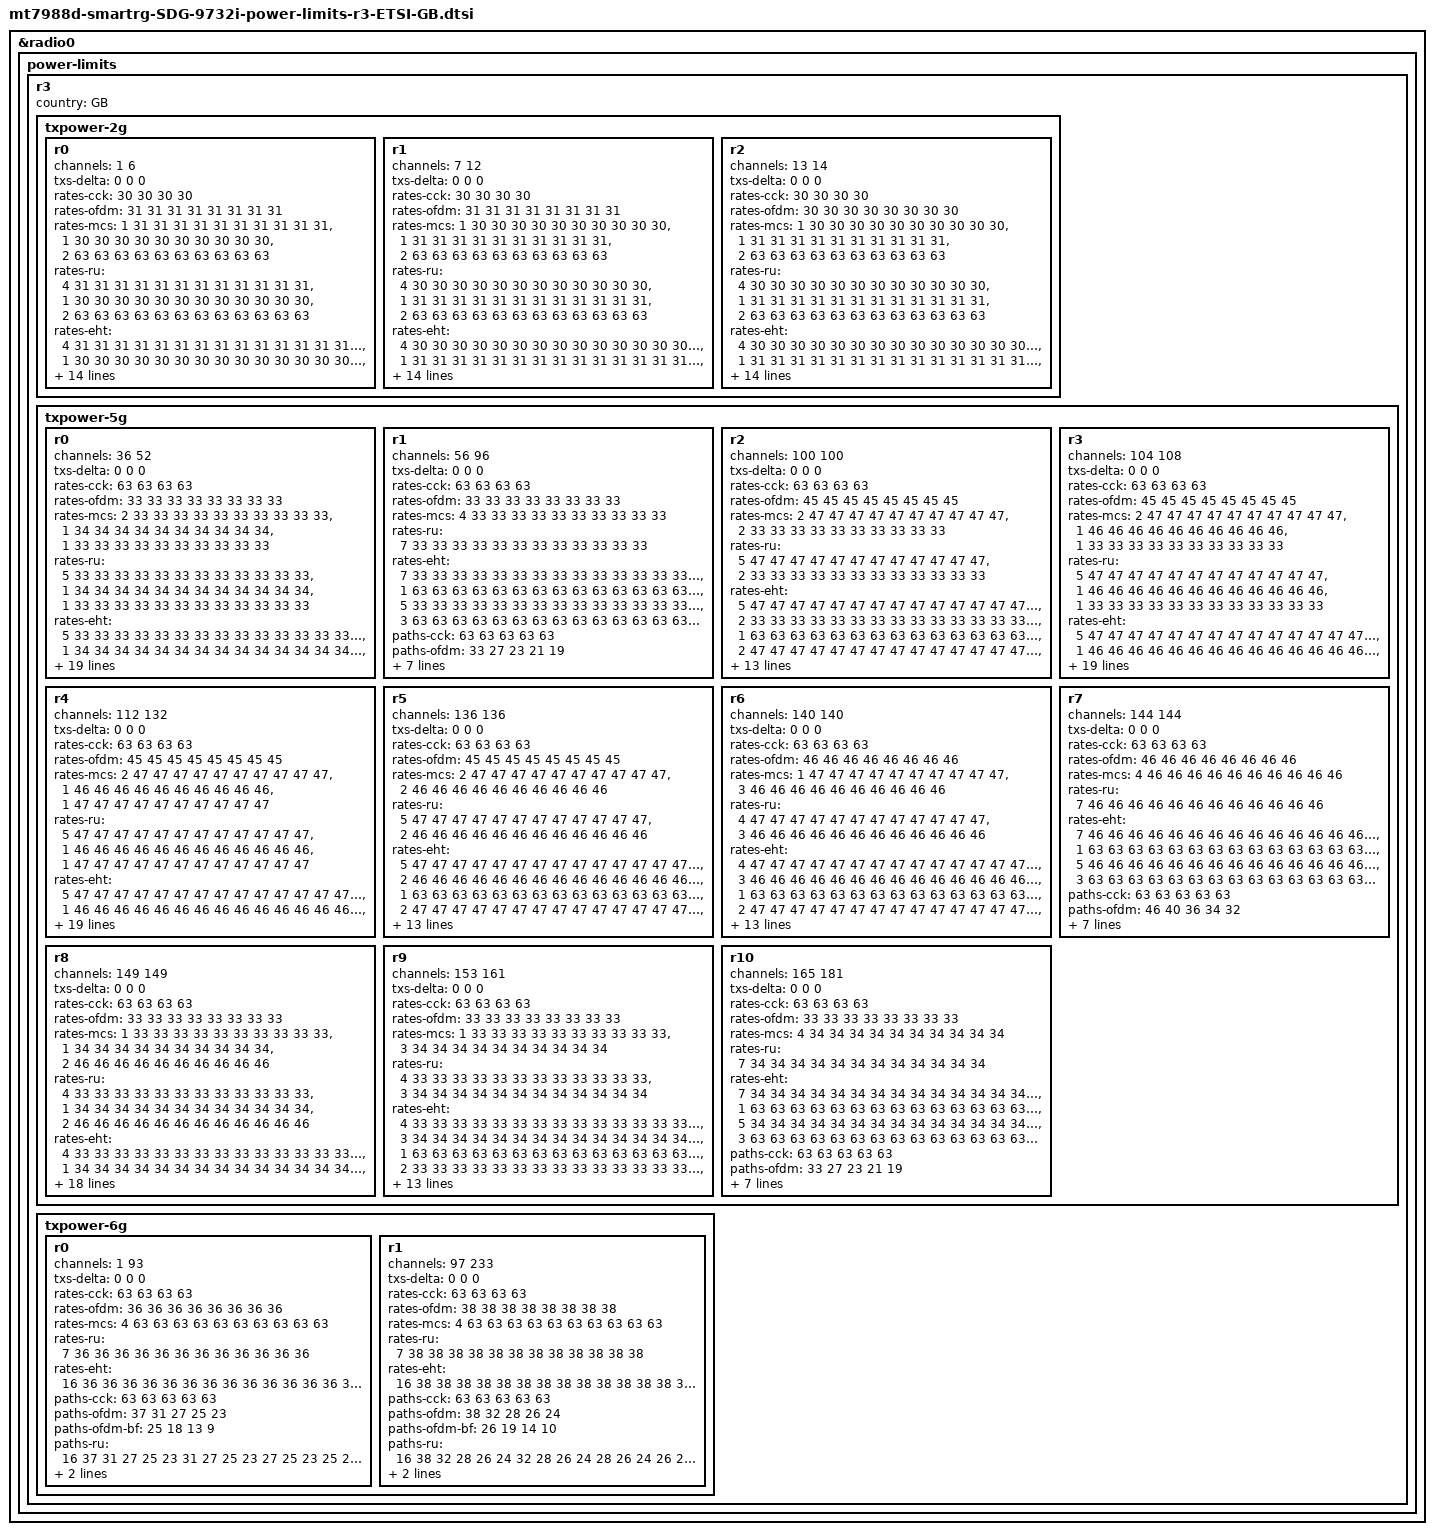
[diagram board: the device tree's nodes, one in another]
// SPDX-License-Identifier: (GPL-2.0 OR MIT)
/*
 * Copyright (C) 2024 SmartRG Inc.
 * Author: Chad Monroe <chad.monroe@smartrg.com>
 */

&radio0 {
	power-limits {
		r3 {
			country = "GB";

			txpower-2g {
				r0 {
					channels = <1 6>;
					txs-delta = <0 0 0>;
					rates-cck = /bits/ 8 <30 30 30 30>;
					rates-ofdm = /bits/ 8 <31 31 31 31 31 31 31 31>;
					rates-mcs =
					/bits/ 8 <1 31 31 31 31 31 31 31 31 31 31>,
					/bits/ 8 <1 30 30 30 30 30 30 30 30 30 30>,
					/bits/ 8 <2 63 63 63 63 63 63 63 63 63 63>;
					rates-ru =
					/bits/ 8 <4 31 31 31 31 31 31 31 31 31 31 31 31>,
					/bits/ 8 <1 30 30 30 30 30 30 30 30 30 30 30 30>,
					/bits/ 8 <2 63 63 63 63 63 63 63 63 63 63 63 63>;
					rates-eht =
					/bits/ 8 <4 31 31 31 31 31 31 31 31 31 31 31 31 31 31 31 31>,
					/bits/ 8 <1 30 30 30 30 30 30 30 30 30 30 30 30 30 30 30 30>,
					/bits/ 8 <3 63 63 63 63 63 63 63 63 63 63 63 63 63 63 63 63>,
					/bits/ 8 <2 31 31 31 31 31 31 31 31 31 31 31 31 31 31 31 31>,
					/bits/ 8 <6 63 63 63 63 63 63 63 63 63 63 63 63 63 63 63 63>;
					paths-cck = /bits/ 8 <30 24 20 18 16>;
					paths-ofdm = /bits/ 8 <31 25 21 19 17>;
					paths-ofdm-bf = /bits/ 8 <19 12 7 3>;
					paths-ru =
					/bits/ 8 <6 31 25 21 19 17 25 21 19 17 21 19 17 19 17 17>,
					/bits/ 8 <1 30 24 20 18 16 24 20 18 16 20 18 16 18 16 16>,
					/bits/ 8 <9 63 63 63 63 63 63 63 63 63 63 63 63 63 63 63>;
					paths-ru-bf =
					/bits/ 8 <6 31 19 12 7 3 25 18 13 9 21 16 13 19 15 17>,
					/bits/ 8 <1 30 18 11 6 2 24 17 12 8 20 15 12 18 14 16>,
					/bits/ 8 <9 63 63 63 63 63 63 63 63 63 63 63 63 63 63 63>;
				};
				r1 {
					channels = <7 12>;
					txs-delta = <0 0 0>;
					rates-cck = /bits/ 8 <30 30 30 30>;
					rates-ofdm = /bits/ 8 <31 31 31 31 31 31 31 31>;
					rates-mcs =
					/bits/ 8 <1 30 30 30 30 30 30 30 30 30 30>,
					/bits/ 8 <1 31 31 31 31 31 31 31 31 31 31>,
					/bits/ 8 <2 63 63 63 63 63 63 63 63 63 63>;
					rates-ru =
					/bits/ 8 <4 30 30 30 30 30 30 30 30 30 30 30 30>,
					/bits/ 8 <1 31 31 31 31 31 31 31 31 31 31 31 31>,
					/bits/ 8 <2 63 63 63 63 63 63 63 63 63 63 63 63>;
					rates-eht =
					/bits/ 8 <4 30 30 30 30 30 30 30 30 30 30 30 30 30 30 30 30>,
					/bits/ 8 <1 31 31 31 31 31 31 31 31 31 31 31 31 31 31 31 31>,
					/bits/ 8 <3 63 63 63 63 63 63 63 63 63 63 63 63 63 63 63 63>,
					/bits/ 8 <2 30 30 30 30 30 30 30 30 30 30 30 30 30 30 30 30>,
					/bits/ 8 <6 63 63 63 63 63 63 63 63 63 63 63 63 63 63 63 63>;
					paths-cck = /bits/ 8 <30 24 20 18 16>;
					paths-ofdm = /bits/ 8 <31 25 21 19 17>;
					paths-ofdm-bf = /bits/ 8 <19 12 7 3>;
					paths-ru =
					/bits/ 8 <6 30 24 20 18 16 24 20 18 16 20 18 16 18 16 16>,
					/bits/ 8 <1 31 25 21 19 17 25 21 19 17 21 19 17 19 17 17>,
					/bits/ 8 <9 63 63 63 63 63 63 63 63 63 63 63 63 63 63 63>;
					paths-ru-bf =
					/bits/ 8 <6 30 18 11 6 2 24 17 12 8 20 15 12 18 14 16>,
					/bits/ 8 <1 31 19 12 7 3 25 18 13 9 21 16 13 19 15 17>,
					/bits/ 8 <9 63 63 63 63 63 63 63 63 63 63 63 63 63 63 63>;
				};
				r2 {
					channels = <13 14>;
					txs-delta = <0 0 0>;
					rates-cck = /bits/ 8 <30 30 30 30>;
					rates-ofdm = /bits/ 8 <30 30 30 30 30 30 30 30>;
					rates-mcs =
					/bits/ 8 <1 30 30 30 30 30 30 30 30 30 30>,
					/bits/ 8 <1 31 31 31 31 31 31 31 31 31 31>,
					/bits/ 8 <2 63 63 63 63 63 63 63 63 63 63>;
					rates-ru =
					/bits/ 8 <4 30 30 30 30 30 30 30 30 30 30 30 30>,
					/bits/ 8 <1 31 31 31 31 31 31 31 31 31 31 31 31>,
					/bits/ 8 <2 63 63 63 63 63 63 63 63 63 63 63 63>;
					rates-eht =
					/bits/ 8 <4 30 30 30 30 30 30 30 30 30 30 30 30 30 30 30 30>,
					/bits/ 8 <1 31 31 31 31 31 31 31 31 31 31 31 31 31 31 31 31>,
					/bits/ 8 <3 63 63 63 63 63 63 63 63 63 63 63 63 63 63 63 63>,
					/bits/ 8 <2 30 30 30 30 30 30 30 30 30 30 30 30 30 30 30 30>,
					/bits/ 8 <6 63 63 63 63 63 63 63 63 63 63 63 63 63 63 63 63>;
					paths-cck = /bits/ 8 <30 24 20 18 16>;
					paths-ofdm = /bits/ 8 <30 24 20 18 16>;
					paths-ofdm-bf = /bits/ 8 <18 11 6 2>;
					paths-ru =
					/bits/ 8 <6 30 24 20 18 16 24 20 18 16 20 18 16 18 16 16>,
					/bits/ 8 <1 31 25 21 19 17 25 21 19 17 21 19 17 19 17 17>,
					/bits/ 8 <9 63 63 63 63 63 63 63 63 63 63 63 63 63 63 63>;
					paths-ru-bf =
					/bits/ 8 <6 30 18 11 6 2 24 17 12 8 20 15 12 18 14 16>,
					/bits/ 8 <1 31 19 12 7 3 25 18 13 9 21 16 13 19 15 17>,
					/bits/ 8 <9 63 63 63 63 63 63 63 63 63 63 63 63 63 63 63>;
				};
			};
			txpower-5g {
				r0 {
					channels = <36 52>;
					txs-delta = <0 0 0>;
					rates-cck = /bits/ 8 <63 63 63 63>;
					rates-ofdm = /bits/ 8 <33 33 33 33 33 33 33 33>;
					rates-mcs =
					/bits/ 8 <2 33 33 33 33 33 33 33 33 33 33>,
					/bits/ 8 <1 34 34 34 34 34 34 34 34 34 34>,
					/bits/ 8 <1 33 33 33 33 33 33 33 33 33 33>;
					rates-ru =
					/bits/ 8 <5 33 33 33 33 33 33 33 33 33 33 33 33>,
					/bits/ 8 <1 34 34 34 34 34 34 34 34 34 34 34 34>,
					/bits/ 8 <1 33 33 33 33 33 33 33 33 33 33 33 33>;
					rates-eht =
					/bits/ 8 <5 33 33 33 33 33 33 33 33 33 33 33 33 33 33 33 33>,
					/bits/ 8 <1 34 34 34 34 34 34 34 34 34 34 34 34 34 34 34 34>,
					/bits/ 8 <1 33 33 33 33 33 33 33 33 33 33 33 33 33 33 33 33>,
					/bits/ 8 <1 63 63 63 63 63 63 63 63 63 63 63 63 63 63 63 63>,
					/bits/ 8 <2 33 33 33 33 33 33 33 33 33 33 33 33 33 33 33 33>,
					/bits/ 8 <1 34 34 34 34 34 34 34 34 34 34 34 34 34 34 34 34>,
					/bits/ 8 <2 33 33 33 33 33 33 33 33 33 33 33 33 33 33 33 33>,
					/bits/ 8 <3 63 63 63 63 63 63 63 63 63 63 63 63 63 63 63 63>;
					paths-cck = /bits/ 8 <63 63 63 63 63>;
					paths-ofdm = /bits/ 8 <33 27 23 21 19>;
					paths-ofdm-bf = /bits/ 8 <21 14 9 5>;
					paths-ru =
					/bits/ 8 <7 33 27 23 21 19 27 23 21 19 23 21 19 21 19 19>,
					/bits/ 8 <2 34 28 24 22 20 28 24 22 20 24 22 20 22 20 20>,
					/bits/ 8 <3 33 27 23 21 19 27 23 21 19 23 21 19 21 19 19>,
					/bits/ 8 <4 63 63 63 63 63 63 63 63 63 63 63 63 63 63 63>;
					paths-ru-bf =
					/bits/ 8 <7 33 21 14 9 5 27 20 15 11 23 18 15 21 17 19>,
					/bits/ 8 <2 34 22 15 10 6 28 21 16 12 24 19 16 22 18 20>,
					/bits/ 8 <3 33 21 14 9 5 27 20 15 11 23 18 15 21 17 19>,
					/bits/ 8 <4 63 63 63 63 63 63 63 63 63 63 63 63 63 63 63>;
				};
				r1 {
					channels = <56 96>;
					txs-delta = <0 0 0>;
					rates-cck = /bits/ 8 <63 63 63 63>;
					rates-ofdm = /bits/ 8 <33 33 33 33 33 33 33 33>;
					rates-mcs =
					/bits/ 8 <4 33 33 33 33 33 33 33 33 33 33>;
					rates-ru =
					/bits/ 8 <7 33 33 33 33 33 33 33 33 33 33 33 33>;
					rates-eht =
					/bits/ 8 <7 33 33 33 33 33 33 33 33 33 33 33 33 33 33 33 33>,
					/bits/ 8 <1 63 63 63 63 63 63 63 63 63 63 63 63 63 63 63 63>,
					/bits/ 8 <5 33 33 33 33 33 33 33 33 33 33 33 33 33 33 33 33>,
					/bits/ 8 <3 63 63 63 63 63 63 63 63 63 63 63 63 63 63 63 63>;
					paths-cck = /bits/ 8 <63 63 63 63 63>;
					paths-ofdm = /bits/ 8 <33 27 23 21 19>;
					paths-ofdm-bf = /bits/ 8 <21 14 9 5>;
					paths-ru =
					/bits/ 8 <12 33 27 23 21 19 27 23 21 19 23 21 19 21 19 19>,
					/bits/ 8 <4 63 63 63 63 63 63 63 63 63 63 63 63 63 63 63>;
					paths-ru-bf =
					/bits/ 8 <12 33 21 14 9 5 27 20 15 11 23 18 15 21 17 19>,
					/bits/ 8 <4 63 63 63 63 63 63 63 63 63 63 63 63 63 63 63>;
				};
				r2 {
					channels = <100 100>;
					txs-delta = <0 0 0>;
					rates-cck = /bits/ 8 <63 63 63 63>;
					rates-ofdm = /bits/ 8 <45 45 45 45 45 45 45 45>;
					rates-mcs =
					/bits/ 8 <2 47 47 47 47 47 47 47 47 47 47>,
					/bits/ 8 <2 33 33 33 33 33 33 33 33 33 33>;
					rates-ru =
					/bits/ 8 <5 47 47 47 47 47 47 47 47 47 47 47 47>,
					/bits/ 8 <2 33 33 33 33 33 33 33 33 33 33 33 33>;
					rates-eht =
					/bits/ 8 <5 47 47 47 47 47 47 47 47 47 47 47 47 47 47 47 47>,
					/bits/ 8 <2 33 33 33 33 33 33 33 33 33 33 33 33 33 33 33 33>,
					/bits/ 8 <1 63 63 63 63 63 63 63 63 63 63 63 63 63 63 63 63>,
					/bits/ 8 <2 47 47 47 47 47 47 47 47 47 47 47 47 47 47 47 47>,
					/bits/ 8 <3 33 33 33 33 33 33 33 33 33 33 33 33 33 33 33 33>,
					/bits/ 8 <3 63 63 63 63 63 63 63 63 63 63 63 63 63 63 63 63>;
					paths-cck = /bits/ 8 <63 63 63 63 63>;
					paths-ofdm = /bits/ 8 <45 39 35 33 31>;
					paths-ofdm-bf = /bits/ 8 <33 26 21 17>;
					paths-ru =
					/bits/ 8 <7 47 41 37 35 33 41 37 35 33 37 35 33 35 33 33>,
					/bits/ 8 <5 33 27 23 21 19 27 23 21 19 23 21 19 21 19 19>,
					/bits/ 8 <4 63 63 63 63 63 63 63 63 63 63 63 63 63 63 63>;
					paths-ru-bf =
					/bits/ 8 <7 47 35 28 23 19 41 34 29 25 37 32 29 35 31 33>,
					/bits/ 8 <5 33 21 14 9 5 27 20 15 11 23 18 15 21 17 19>,
					/bits/ 8 <4 63 63 63 63 63 63 63 63 63 63 63 63 63 63 63>;
				};
				r3 {
					channels = <104 108>;
					txs-delta = <0 0 0>;
					rates-cck = /bits/ 8 <63 63 63 63>;
					rates-ofdm = /bits/ 8 <45 45 45 45 45 45 45 45>;
					rates-mcs =
					/bits/ 8 <2 47 47 47 47 47 47 47 47 47 47>,
					/bits/ 8 <1 46 46 46 46 46 46 46 46 46 46>,
					/bits/ 8 <1 33 33 33 33 33 33 33 33 33 33>;
					rates-ru =
					/bits/ 8 <5 47 47 47 47 47 47 47 47 47 47 47 47>,
					/bits/ 8 <1 46 46 46 46 46 46 46 46 46 46 46 46>,
					/bits/ 8 <1 33 33 33 33 33 33 33 33 33 33 33 33>;
					rates-eht =
					/bits/ 8 <5 47 47 47 47 47 47 47 47 47 47 47 47 47 47 47 47>,
					/bits/ 8 <1 46 46 46 46 46 46 46 46 46 46 46 46 46 46 46 46>,
					/bits/ 8 <1 33 33 33 33 33 33 33 33 33 33 33 33 33 33 33 33>,
					/bits/ 8 <1 63 63 63 63 63 63 63 63 63 63 63 63 63 63 63 63>,
					/bits/ 8 <2 47 47 47 47 47 47 47 47 47 47 47 47 47 47 47 47>,
					/bits/ 8 <1 46 46 46 46 46 46 46 46 46 46 46 46 46 46 46 46>,
					/bits/ 8 <2 33 33 33 33 33 33 33 33 33 33 33 33 33 33 33 33>,
					/bits/ 8 <3 63 63 63 63 63 63 63 63 63 63 63 63 63 63 63 63>;
					paths-cck = /bits/ 8 <63 63 63 63 63>;
					paths-ofdm = /bits/ 8 <45 39 35 33 31>;
					paths-ofdm-bf = /bits/ 8 <33 26 21 17>;
					paths-ru =
					/bits/ 8 <7 47 41 37 35 33 41 37 35 33 37 35 33 35 33 33>,
					/bits/ 8 <2 46 40 36 34 32 40 36 34 32 36 34 32 34 32 32>,
					/bits/ 8 <3 33 27 23 21 19 27 23 21 19 23 21 19 21 19 19>,
					/bits/ 8 <4 63 63 63 63 63 63 63 63 63 63 63 63 63 63 63>;
					paths-ru-bf =
					/bits/ 8 <7 47 35 28 23 19 41 34 29 25 37 32 29 35 31 33>,
					/bits/ 8 <2 46 34 27 22 18 40 33 28 24 36 31 28 34 30 32>,
					/bits/ 8 <3 33 21 14 9 5 27 20 15 11 23 18 15 21 17 19>,
					/bits/ 8 <4 63 63 63 63 63 63 63 63 63 63 63 63 63 63 63>;
				};
				r4 {
					channels = <112 132>;
					txs-delta = <0 0 0>;
					rates-cck = /bits/ 8 <63 63 63 63>;
					rates-ofdm = /bits/ 8 <45 45 45 45 45 45 45 45>;
					rates-mcs =
					/bits/ 8 <2 47 47 47 47 47 47 47 47 47 47>,
					/bits/ 8 <1 46 46 46 46 46 46 46 46 46 46>,
					/bits/ 8 <1 47 47 47 47 47 47 47 47 47 47>;
					rates-ru =
					/bits/ 8 <5 47 47 47 47 47 47 47 47 47 47 47 47>,
					/bits/ 8 <1 46 46 46 46 46 46 46 46 46 46 46 46>,
					/bits/ 8 <1 47 47 47 47 47 47 47 47 47 47 47 47>;
					rates-eht =
					/bits/ 8 <5 47 47 47 47 47 47 47 47 47 47 47 47 47 47 47 47>,
					/bits/ 8 <1 46 46 46 46 46 46 46 46 46 46 46 46 46 46 46 46>,
					/bits/ 8 <1 47 47 47 47 47 47 47 47 47 47 47 47 47 47 47 47>,
					/bits/ 8 <1 63 63 63 63 63 63 63 63 63 63 63 63 63 63 63 63>,
					/bits/ 8 <2 47 47 47 47 47 47 47 47 47 47 47 47 47 47 47 47>,
					/bits/ 8 <1 46 46 46 46 46 46 46 46 46 46 46 46 46 46 46 46>,
					/bits/ 8 <2 47 47 47 47 47 47 47 47 47 47 47 47 47 47 47 47>,
					/bits/ 8 <3 63 63 63 63 63 63 63 63 63 63 63 63 63 63 63 63>;
					paths-cck = /bits/ 8 <63 63 63 63 63>;
					paths-ofdm = /bits/ 8 <45 39 35 33 31>;
					paths-ofdm-bf = /bits/ 8 <33 26 21 17>;
					paths-ru =
					/bits/ 8 <7 47 41 37 35 33 41 37 35 33 37 35 33 35 33 33>,
					/bits/ 8 <2 46 40 36 34 32 40 36 34 32 36 34 32 34 32 32>,
					/bits/ 8 <3 47 41 37 35 33 41 37 35 33 37 35 33 35 33 33>,
					/bits/ 8 <4 63 63 63 63 63 63 63 63 63 63 63 63 63 63 63>;
					paths-ru-bf =
					/bits/ 8 <7 47 35 28 23 19 41 34 29 25 37 32 29 35 31 33>,
					/bits/ 8 <2 46 34 27 22 18 40 33 28 24 36 31 28 34 30 32>,
					/bits/ 8 <3 47 35 28 23 19 41 34 29 25 37 32 29 35 31 33>,
					/bits/ 8 <4 63 63 63 63 63 63 63 63 63 63 63 63 63 63 63>;
				};
				r5 {
					channels = <136 136>;
					txs-delta = <0 0 0>;
					rates-cck = /bits/ 8 <63 63 63 63>;
					rates-ofdm = /bits/ 8 <45 45 45 45 45 45 45 45>;
					rates-mcs =
					/bits/ 8 <2 47 47 47 47 47 47 47 47 47 47>,
					/bits/ 8 <2 46 46 46 46 46 46 46 46 46 46>;
					rates-ru =
					/bits/ 8 <5 47 47 47 47 47 47 47 47 47 47 47 47>,
					/bits/ 8 <2 46 46 46 46 46 46 46 46 46 46 46 46>;
					rates-eht =
					/bits/ 8 <5 47 47 47 47 47 47 47 47 47 47 47 47 47 47 47 47>,
					/bits/ 8 <2 46 46 46 46 46 46 46 46 46 46 46 46 46 46 46 46>,
					/bits/ 8 <1 63 63 63 63 63 63 63 63 63 63 63 63 63 63 63 63>,
					/bits/ 8 <2 47 47 47 47 47 47 47 47 47 47 47 47 47 47 47 47>,
					/bits/ 8 <3 46 46 46 46 46 46 46 46 46 46 46 46 46 46 46 46>,
					/bits/ 8 <3 63 63 63 63 63 63 63 63 63 63 63 63 63 63 63 63>;
					paths-cck = /bits/ 8 <63 63 63 63 63>;
					paths-ofdm = /bits/ 8 <45 39 35 33 31>;
					paths-ofdm-bf = /bits/ 8 <33 26 21 17>;
					paths-ru =
					/bits/ 8 <7 47 41 37 35 33 41 37 35 33 37 35 33 35 33 33>,
					/bits/ 8 <5 46 40 36 34 32 40 36 34 32 36 34 32 34 32 32>,
					/bits/ 8 <4 63 63 63 63 63 63 63 63 63 63 63 63 63 63 63>;
					paths-ru-bf =
					/bits/ 8 <7 47 35 28 23 19 41 34 29 25 37 32 29 35 31 33>,
					/bits/ 8 <5 46 34 27 22 18 40 33 28 24 36 31 28 34 30 32>,
					/bits/ 8 <4 63 63 63 63 63 63 63 63 63 63 63 63 63 63 63>;
				};
				r6 {
					channels = <140 140>;
					txs-delta = <0 0 0>;
					rates-cck = /bits/ 8 <63 63 63 63>;
					rates-ofdm = /bits/ 8 <46 46 46 46 46 46 46 46>;
					rates-mcs =
					/bits/ 8 <1 47 47 47 47 47 47 47 47 47 47>,
					/bits/ 8 <3 46 46 46 46 46 46 46 46 46 46>;
					rates-ru =
					/bits/ 8 <4 47 47 47 47 47 47 47 47 47 47 47 47>,
					/bits/ 8 <3 46 46 46 46 46 46 46 46 46 46 46 46>;
					rates-eht =
					/bits/ 8 <4 47 47 47 47 47 47 47 47 47 47 47 47 47 47 47 47>,
					/bits/ 8 <3 46 46 46 46 46 46 46 46 46 46 46 46 46 46 46 46>,
					/bits/ 8 <1 63 63 63 63 63 63 63 63 63 63 63 63 63 63 63 63>,
					/bits/ 8 <2 47 47 47 47 47 47 47 47 47 47 47 47 47 47 47 47>,
					/bits/ 8 <3 46 46 46 46 46 46 46 46 46 46 46 46 46 46 46 46>,
					/bits/ 8 <3 63 63 63 63 63 63 63 63 63 63 63 63 63 63 63 63>;
					paths-cck = /bits/ 8 <63 63 63 63 63>;
					paths-ofdm = /bits/ 8 <46 40 36 34 32>;
					paths-ofdm-bf = /bits/ 8 <34 27 22 18>;
					paths-ru =
					/bits/ 8 <6 47 41 37 35 33 41 37 35 33 37 35 33 35 33 33>,
					/bits/ 8 <6 46 40 36 34 32 40 36 34 32 36 34 32 34 32 32>,
					/bits/ 8 <4 63 63 63 63 63 63 63 63 63 63 63 63 63 63 63>;
					paths-ru-bf =
					/bits/ 8 <6 47 35 28 23 19 41 34 29 25 37 32 29 35 31 33>,
					/bits/ 8 <6 46 34 27 22 18 40 33 28 24 36 31 28 34 30 32>,
					/bits/ 8 <4 63 63 63 63 63 63 63 63 63 63 63 63 63 63 63>;
				};
				r7 {
					channels = <144 144>;
					txs-delta = <0 0 0>;
					rates-cck = /bits/ 8 <63 63 63 63>;
					rates-ofdm = /bits/ 8 <46 46 46 46 46 46 46 46>;
					rates-mcs =
					/bits/ 8 <4 46 46 46 46 46 46 46 46 46 46>;
					rates-ru =
					/bits/ 8 <7 46 46 46 46 46 46 46 46 46 46 46 46>;
					rates-eht =
					/bits/ 8 <7 46 46 46 46 46 46 46 46 46 46 46 46 46 46 46 46>,
					/bits/ 8 <1 63 63 63 63 63 63 63 63 63 63 63 63 63 63 63 63>,
					/bits/ 8 <5 46 46 46 46 46 46 46 46 46 46 46 46 46 46 46 46>,
					/bits/ 8 <3 63 63 63 63 63 63 63 63 63 63 63 63 63 63 63 63>;
					paths-cck = /bits/ 8 <63 63 63 63 63>;
					paths-ofdm = /bits/ 8 <46 40 36 34 32>;
					paths-ofdm-bf = /bits/ 8 <34 27 22 18>;
					paths-ru =
					/bits/ 8 <12 46 40 36 34 32 40 36 34 32 36 34 32 34 32 32>,
					/bits/ 8 <4 63 63 63 63 63 63 63 63 63 63 63 63 63 63 63>;
					paths-ru-bf =
					/bits/ 8 <12 46 34 27 22 18 40 33 28 24 36 31 28 34 30 32>,
					/bits/ 8 <4 63 63 63 63 63 63 63 63 63 63 63 63 63 63 63>;
				};
				r8 {
					channels = <149 149>;
					txs-delta = <0 0 0>;
					rates-cck = /bits/ 8 <63 63 63 63>;
					rates-ofdm = /bits/ 8 <33 33 33 33 33 33 33 33>;
					rates-mcs =
					/bits/ 8 <1 33 33 33 33 33 33 33 33 33 33>,
					/bits/ 8 <1 34 34 34 34 34 34 34 34 34 34>,
					/bits/ 8 <2 46 46 46 46 46 46 46 46 46 46>;
					rates-ru =
					/bits/ 8 <4 33 33 33 33 33 33 33 33 33 33 33 33>,
					/bits/ 8 <1 34 34 34 34 34 34 34 34 34 34 34 34>,
					/bits/ 8 <2 46 46 46 46 46 46 46 46 46 46 46 46>;
					rates-eht =
					/bits/ 8 <4 33 33 33 33 33 33 33 33 33 33 33 33 33 33 33 33>,
					/bits/ 8 <1 34 34 34 34 34 34 34 34 34 34 34 34 34 34 34 34>,
					/bits/ 8 <2 46 46 46 46 46 46 46 46 46 46 46 46 46 46 46 46>,
					/bits/ 8 <1 63 63 63 63 63 63 63 63 63 63 63 63 63 63 63 63>,
					/bits/ 8 <2 33 33 33 33 33 33 33 33 33 33 33 33 33 33 33 33>,
					/bits/ 8 <3 46 46 46 46 46 46 46 46 46 46 46 46 46 46 46 46>,
					/bits/ 8 <3 63 63 63 63 63 63 63 63 63 63 63 63 63 63 63 63>;
					paths-cck = /bits/ 8 <63 63 63 63 63>;
					paths-ofdm = /bits/ 8 <33 27 23 21 19>;
					paths-ofdm-bf = /bits/ 8 <21 14 9 5>;
					paths-ru =
					/bits/ 8 <6 33 27 23 21 19 27 23 21 19 23 21 19 21 19 19>,
					/bits/ 8 <1 34 28 24 22 20 28 24 22 20 24 22 20 22 20 20>,
					/bits/ 8 <5 46 40 36 34 32 40 36 34 32 36 34 32 34 32 32>,
					/bits/ 8 <4 63 63 63 63 63 63 63 63 63 63 63 63 63 63 63>;
					paths-ru-bf =
					/bits/ 8 <6 33 21 14 9 5 27 20 15 11 23 18 15 21 17 19>,
					/bits/ 8 <1 34 22 15 10 6 28 21 16 12 24 19 16 22 18 20>,
					/bits/ 8 <5 46 34 27 22 18 40 33 28 24 36 31 28 34 30 32>,
					/bits/ 8 <4 63 63 63 63 63 63 63 63 63 63 63 63 63 63 63>;
				};
				r9 {
					channels = <153 161>;
					txs-delta = <0 0 0>;
					rates-cck = /bits/ 8 <63 63 63 63>;
					rates-ofdm = /bits/ 8 <33 33 33 33 33 33 33 33>;
					rates-mcs =
					/bits/ 8 <1 33 33 33 33 33 33 33 33 33 33>,
					/bits/ 8 <3 34 34 34 34 34 34 34 34 34 34>;
					rates-ru =
					/bits/ 8 <4 33 33 33 33 33 33 33 33 33 33 33 33>,
					/bits/ 8 <3 34 34 34 34 34 34 34 34 34 34 34 34>;
					rates-eht =
					/bits/ 8 <4 33 33 33 33 33 33 33 33 33 33 33 33 33 33 33 33>,
					/bits/ 8 <3 34 34 34 34 34 34 34 34 34 34 34 34 34 34 34 34>,
					/bits/ 8 <1 63 63 63 63 63 63 63 63 63 63 63 63 63 63 63 63>,
					/bits/ 8 <2 33 33 33 33 33 33 33 33 33 33 33 33 33 33 33 33>,
					/bits/ 8 <3 34 34 34 34 34 34 34 34 34 34 34 34 34 34 34 34>,
					/bits/ 8 <3 63 63 63 63 63 63 63 63 63 63 63 63 63 63 63 63>;
					paths-cck = /bits/ 8 <63 63 63 63 63>;
					paths-ofdm = /bits/ 8 <33 27 23 21 19>;
					paths-ofdm-bf = /bits/ 8 <21 14 9 5>;
					paths-ru =
					/bits/ 8 <6 33 27 23 21 19 27 23 21 19 23 21 19 21 19 19>,
					/bits/ 8 <6 34 28 24 22 20 28 24 22 20 24 22 20 22 20 20>,
					/bits/ 8 <4 63 63 63 63 63 63 63 63 63 63 63 63 63 63 63>;
					paths-ru-bf =
					/bits/ 8 <6 33 21 14 9 5 27 20 15 11 23 18 15 21 17 19>,
					/bits/ 8 <6 34 22 15 10 6 28 21 16 12 24 19 16 22 18 20>,
					/bits/ 8 <4 63 63 63 63 63 63 63 63 63 63 63 63 63 63 63>;
				};
				r10 {
					channels = <165 181>;
					txs-delta = <0 0 0>;
					rates-cck = /bits/ 8 <63 63 63 63>;
					rates-ofdm = /bits/ 8 <33 33 33 33 33 33 33 33>;
					rates-mcs =
					/bits/ 8 <4 34 34 34 34 34 34 34 34 34 34>;
					rates-ru =
					/bits/ 8 <7 34 34 34 34 34 34 34 34 34 34 34 34>;
					rates-eht =
					/bits/ 8 <7 34 34 34 34 34 34 34 34 34 34 34 34 34 34 34 34>,
					/bits/ 8 <1 63 63 63 63 63 63 63 63 63 63 63 63 63 63 63 63>,
					/bits/ 8 <5 34 34 34 34 34 34 34 34 34 34 34 34 34 34 34 34>,
					/bits/ 8 <3 63 63 63 63 63 63 63 63 63 63 63 63 63 63 63 63>;
					paths-cck = /bits/ 8 <63 63 63 63 63>;
					paths-ofdm = /bits/ 8 <33 27 23 21 19>;
					paths-ofdm-bf = /bits/ 8 <21 14 9 5>;
					paths-ru =
					/bits/ 8 <12 34 28 24 22 20 28 24 22 20 24 22 20 22 20 20>,
					/bits/ 8 <4 63 63 63 63 63 63 63 63 63 63 63 63 63 63 63>;
					paths-ru-bf =
					/bits/ 8 <12 34 22 15 10 6 28 21 16 12 24 19 16 22 18 20>,
					/bits/ 8 <4 63 63 63 63 63 63 63 63 63 63 63 63 63 63 63>;
				};
			};
			txpower-6g {
				r0 {
					channels = <1 93>;
					txs-delta = <0 0 0>;
					rates-cck = /bits/ 8 <63 63 63 63>;
					rates-ofdm = /bits/ 8 <36 36 36 36 36 36 36 36>;
					rates-mcs =
					/bits/ 8 <4 63 63 63 63 63 63 63 63 63 63>;
					rates-ru =
					/bits/ 8 <7 36 36 36 36 36 36 36 36 36 36 36 36>;
					rates-eht =
					/bits/ 8 <16 36 36 36 36 36 36 36 36 36 36 36 36 36 36 36 36>;
					paths-cck = /bits/ 8 <63 63 63 63 63>;
					paths-ofdm = /bits/ 8 <37 31 27 25 23>;
					paths-ofdm-bf = /bits/ 8 <25 18 13 9>;
					paths-ru =
					/bits/ 8 <16 37 31 27 25 23 31 27 25 23 27 25 23 25 23 23>;
					paths-ru-bf =
					/bits/ 8 <16 37 25 18 13 9 31 24 19 15 27 22 18 25 21 23>;
				};
				r1 {
					channels = <97 233>;
					txs-delta = <0 0 0>;
					rates-cck = /bits/ 8 <63 63 63 63>;
					rates-ofdm = /bits/ 8 <38 38 38 38 38 38 38 38>;
					rates-mcs =
					/bits/ 8 <4 63 63 63 63 63 63 63 63 63 63>;
					rates-ru =
					/bits/ 8 <7 38 38 38 38 38 38 38 38 38 38 38 38>;
					rates-eht =
					/bits/ 8 <16 38 38 38 38 38 38 38 38 38 38 38 38 38 38 38 38>;
					paths-cck = /bits/ 8 <63 63 63 63 63>;
					paths-ofdm = /bits/ 8 <38 32 28 26 24>;
					paths-ofdm-bf = /bits/ 8 <26 19 14 10>;
					paths-ru =
					/bits/ 8 <16 38 32 28 26 24 32 28 26 24 28 26 24 26 24 24>;
					paths-ru-bf =
					/bits/ 8 <16 38 26 19 14 10 32 25 20 16 28 23 20 26 22 24>;
				};
			};
		};
	};
};
